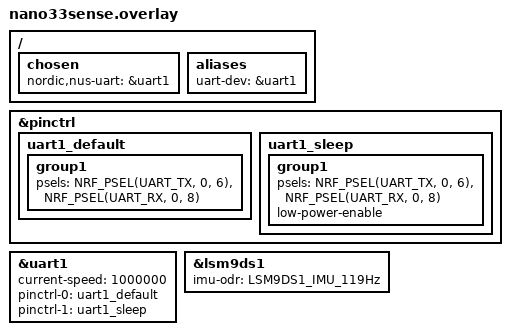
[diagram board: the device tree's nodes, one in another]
#include <zephyr/dt-bindings/sensor/lsm9ds1.h>
 
/ {
    chosen {
        nordic,nus-uart=&uart1;
    };

    aliases {
        uart-dev = &uart1;
    };
};

&pinctrl { 
    uart1_default: uart1_default { 
        group1 { 
            psels = <NRF_PSEL(UART_TX, 0, 6)>, <NRF_PSEL(UART_RX, 0, 8)>; 
        }; 
    }; 
    uart1_sleep: uart1_sleep { 
        group1 { 
            psels = <NRF_PSEL(UART_TX, 0, 6)>, <NRF_PSEL(UART_RX, 0, 8)>; 
            low-power-enable; 
        }; 
    }; 
};

&uart1 {
    status = "okay"; 
    current-speed = <1000000>;
    pinctrl-0 = < &uart1_default >;
    pinctrl-1 = < &uart1_sleep >;
    pinctrl-names = "default", "sleep";
    /* Additional properties if needed */ 
};

&lsm9ds1 {
    imu-odr = <LSM9DS1_IMU_119Hz>;
    //imu-odr = <0x33>;
};

